# STM32F7x7 register map
File version: 1.6
CPU: CM7 r0p0, little endian, no MPU, no FPU, 3 interrupt priority bits
Registers are 32-bit, read-write, reset 0x0 unless marked. A register's access mark holds for its fields unless they carry their own. Offsets are from the block's base; [hi:lo] are bit positions; {n}, {i} and the like mark numbered series.

## MDIOS — Management data input/output slave
Base 0x40017800
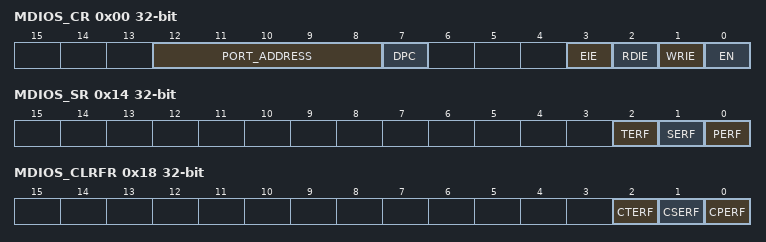
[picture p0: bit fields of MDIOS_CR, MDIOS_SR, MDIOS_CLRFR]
0x00 MDIOS_CR — MDIOS configuration register
  [12:8] PORT_ADDRESS — Slaves's address
  [7] DPC — Disable Preamble Check
  [3] EIE — Error interrupt enable
  [2] RDIE — Register Read Interrupt Enable
  [1] WRIE — Register write interrupt enable
  [0] EN — Peripheral enable
0x04 MDIOS_WRFR ro — MDIOS write flag register
  [31:0] WRF — Write flags for MDIO registers 0 to 31
0x08 MDIOS_CWRFR — MDIOS clear write flag register
  [31:0] CWRF — Clear the write flag
0x0C MDIOS_RDFR ro — MDIOS read flag register
  [31:0] RDF — Read flags for MDIO registers 0 to 31
0x10 MDIOS_CRDFR — MDIOS clear read flag register
  [31:0] CRDF — Clear the read flag
0x14 MDIOS_SR ro — MDIOS status register
  [2] TERF — Turnaround error flag
  [1] SERF — Start error flag
  [0] PERF — Preamble error flag
0x18 MDIOS_CLRFR — MDIOS clear flag register
  [2] CTERF — Clear the turnaround error flag
  [1] CSERF — Clear the start error flag
  [0] CPERF — Clear the preamble error flag
{0x1C+4i} MDIOS_DINR{i} ro (i=0..31) — MDIOS input data register {i}
  [15:0] DIN{i} — Input data received from MDIO Master during write frames
{0x9C+4i} MDIOS_DOUTR{i} (i=0..31) — MDIOS output data register {i}
  [15:0] DOUT{i} — Output data sent to MDIO Master during read frames

## JPEG — JPEG codec
Base 0x50051000
0x00 JPEG_CONFR0 wo — JPEG codec configuration register 0
  [0] START
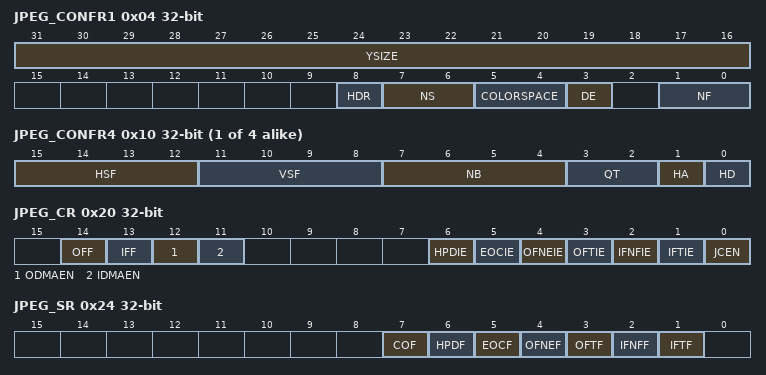
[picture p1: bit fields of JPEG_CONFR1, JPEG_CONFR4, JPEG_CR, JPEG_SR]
0x04 JPEG_CONFR1 — JPEG codec configuration register 1
  [31:16] YSIZE
  [8] HDR — Header Processing
  [7:6] NS — Number of components for Scan
  [5:4] COLORSPACE
  [3] DE — Decoding Enable
  [1:0] NF — Number of color components
0x08 JPEG_CONFR2 — JPEG codec configuration register 2
  [25:0] NMCU — Number of MCU
0x0C JPEG_CONFR3 — JPEG codec configuration register 3
  [31:16] XSIZE
{0x0+4i} JPEG_CONFR{i} (i=4..7) — JPEG codec configuration register {i}
  [15:12] HSF — Horizontal Sampling Factor
  [11:8] VSF — Vertical Sampling Factor
  [7:4] NB — Number of Block
  [3:2] QT — Quantization Table
  [1] HA — Huffman AC
  [0] HD — Huffman DC
0x20 JPEG_CR access per field — JPEG control register
  [14] OFF ro — Output FIFO Flush
  [13] IFF ro — Input FIFO Flush
  [12] ODMAEN rw — Output DMA Enable
  [11] IDMAEN rw — Input DMA Enable
  [6] HPDIE rw — Header Parsing Done Interrupt Enable
  [5] EOCIE rw — End of Conversion Interrupt Enable
  [4] OFNEIE rw — Output FIFO Not Empty Interrupt Enable
  [3] OFTIE rw — Output FIFO Threshold Interrupt Enable
  [2] IFNFIE rw — Input FIFO Not Full Interrupt Enable
  [1] IFTIE rw — Input FIFO Threshold Interrupt Enable
  [0] JCEN rw — JPEG Core Enable
0x24 JPEG_SR ro — JPEG status register
  [7] COF — Codec Operation Flag
  [6] HPDF — Header Parsing Done Flag
  [5] EOCF — End of Conversion Flag
  [4] OFNEF — Output FIFO Not Empty Flag
  [3] OFTF — Output FIFO Threshold Flag
  [2] IFNFF — Input FIFO Not Full Flag
  [1] IFTF — Input FIFO Threshold Flag
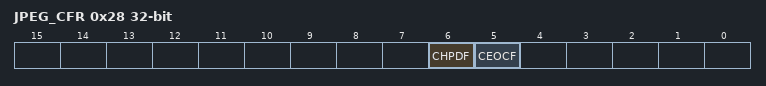
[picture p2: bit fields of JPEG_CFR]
0x28 JPEG_CFR wo — JPEG clear flag register
  [6] CHPDF — Clear Header Parsing Done Flag
  [5] CEOCF — Clear End of Conversion Flag
0x2C JPEG_DIR wo — JPEG data input register
  [31:0] DATAIN — Data Input FIFO
0x30 JPEG_DOR ro — JPEG data output register
  [31:0] DATAOUT — Data Output FIFO

## Ethernet_MMC — Ethernet: MAC management counters
Base 0x40028100
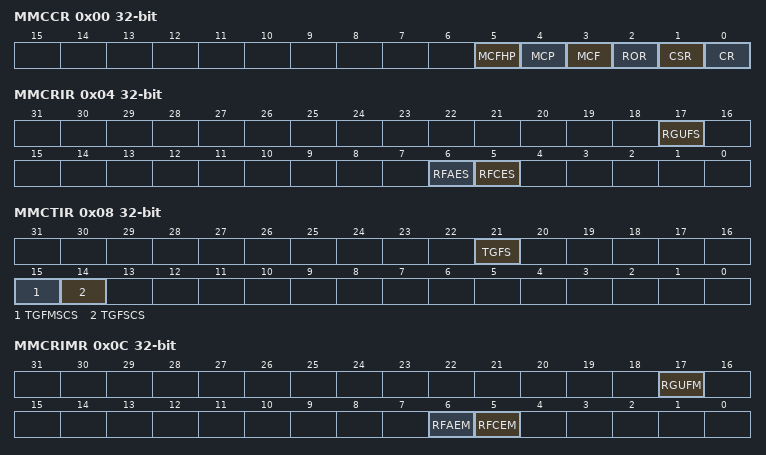
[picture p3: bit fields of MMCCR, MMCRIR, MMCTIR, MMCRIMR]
0x00 MMCCR — Ethernet MMC control register
  [5] MCFHP, [4] MCP, [3] MCF, [2] ROR, [1] CSR, [0] CR
0x04 MMCRIR — Ethernet MMC receive interrupt register
  [17] RGUFS, [6] RFAES, [5] RFCES
0x08 MMCTIR ro — Ethernet MMC transmit interrupt register
  [21] TGFS, [15] TGFMSCS, [14] TGFSCS
0x0C MMCRIMR — Ethernet MMC receive interrupt mask register
  [17] RGUFM, [6] RFAEM, [5] RFCEM
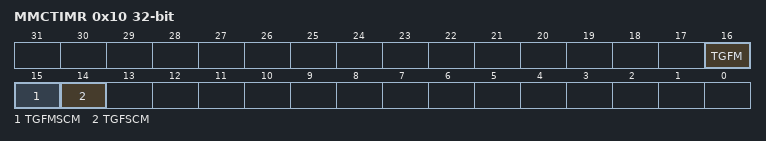
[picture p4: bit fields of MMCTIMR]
0x10 MMCTIMR — Ethernet MMC transmit interrupt mask register
  [16] TGFM, [15] TGFMSCM, [14] TGFSCM
0x4C MMCTGFSCCR ro — Ethernet MMC transmitted good frames after a single collision counter
  [31:0] TGFSCC
0x50 MMCTGFMSCCR ro — Ethernet MMC transmitted good frames after more than a single collision
  [31:0] TGFMSCC
0x68 MMCTGFCR ro — Ethernet MMC transmitted good frames counter register
  [31:0] TGFC — HTL
0x94 MMCRFCECR ro — Ethernet MMC received frames with CRC error counter register
  [31:0] RFCFC
0x98 MMCRFAECR ro — Ethernet MMC received frames with alignment error counter register
  [31:0] RFAEC
0xC4 MMCRGUFCR ro — MMC received good unicast frames counter register
  [31:0] RGUFC
